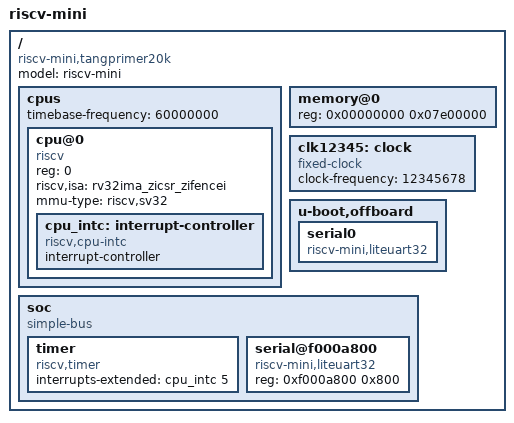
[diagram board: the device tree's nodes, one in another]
// SPDX-License-Identifier: GPL-2.0+
/*
 * U-Boot's own device tree (S-mode payload view). The kernel receives
 * the OpenSBI DTB (build/opensbi/firmware/riscv_mini.dts) via booti,
 * not this file. Memory matches the OpenSBI DTB so dram_init sizes the
 * bank from the same description; the firmware region 0x01000000..0x010fffff
 * is deliberately outside this bank.
 */
/dts-v1/;

/ {
	#address-cells = <1>;
	#size-cells = <1>;
	compatible = "riscv-mini,tangprimer20k";
	model = "riscv-mini";

	cpus {
		#address-cells = <1>;
		#size-cells = <0>;
		timebase-frequency = <60000000>;
		cpu@0 {
			device_type = "cpu";
			reg = <0>;
			compatible = "riscv";
			riscv,isa = "rv32ima_zicsr_zifencei";
			mmu-type = "riscv,sv32";
			cpu_intc: interrupt-controller {
				#interrupt-cells = <1>;
				interrupt-controller;
				compatible = "riscv,cpu-intc";
			};
		};
	};

	memory@0 {
		device_type = "memory";
		reg = <0x00000000 0x07e00000>;
	};

	clk12345: clock {
		compatible = "fixed-clock";
		#clock-cells = <0>;
		clock-frequency = <12345678>;
	};

	u-boot,offboard {
		serial0 {
			compatible = "riscv-mini,liteuart32";
		};
	};

	soc {
		#address-cells = <1>;
		#size-cells = <1>;
		compatible = "simple-bus";
		ranges;

		timer {
			compatible = "riscv,timer";
			interrupts-extended = <&cpu_intc 5>;
		};

		serial@f000a800 {
			compatible = "riscv-mini,liteuart32";
			reg = <0xf000a800 0x800>;
		};
	};
};
